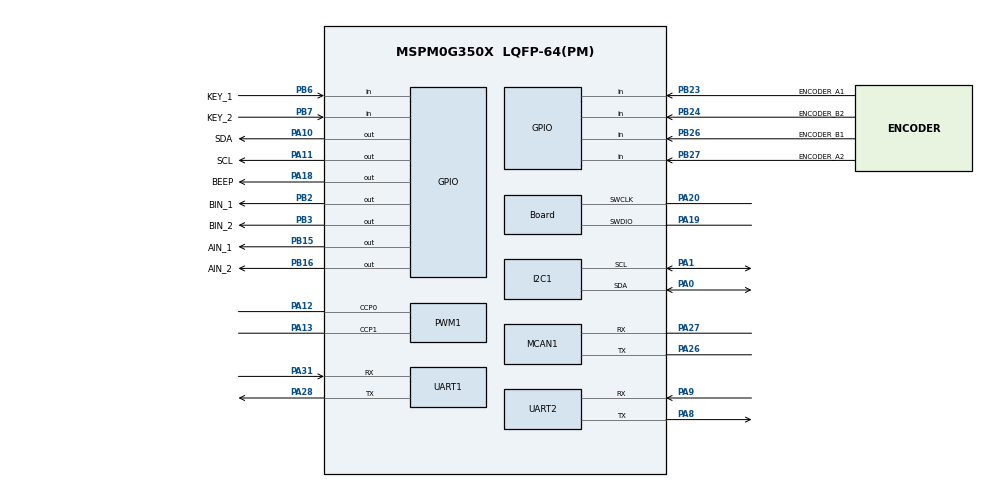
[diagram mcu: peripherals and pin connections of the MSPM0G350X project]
 /**
 * @cliArgs --device "MSPM0G350X" --part "Default" --package "LQFP-64(PM)" --product "mspm0_sdk@2.06.00.05"
 * @versions {"tool":"1.25.0+4268"}
 */

/**
 * Import the modules used in this configuration.
 */
const Board         = scripting.addModule("/ti/driverlib/Board");
const GPIO          = scripting.addModule("/ti/driverlib/GPIO", {}, false);
const GPIO1         = GPIO.addInstance();
const GPIO2         = GPIO.addInstance();
const GPIO3         = GPIO.addInstance();
const GPIO4         = GPIO.addInstance();
const GPIO5         = GPIO.addInstance();
const GPIO6         = GPIO.addInstance();
const I2C           = scripting.addModule("/ti/driverlib/I2C", {}, false);
const I2C1          = I2C.addInstance();
const MCAN          = scripting.addModule("/ti/driverlib/MCAN", {}, false);
const MCAN1         = MCAN.addInstance();
const PWM           = scripting.addModule("/ti/driverlib/PWM", {}, false);
const PWM1          = PWM.addInstance();
const SYSCTL        = scripting.addModule("/ti/driverlib/SYSCTL");
const TIMER         = scripting.addModule("/ti/driverlib/TIMER", {}, false);
const TIMER1        = TIMER.addInstance();
const UART          = scripting.addModule("/ti/driverlib/UART", {}, false);
const UART1         = UART.addInstance();
const UART2         = UART.addInstance();
const ProjectConfig = scripting.addModule("/ti/project_config/ProjectConfig");

/**
 * Write custom configuration values to the imported modules.
 */
const divider6       = system.clockTree["PLL_CLK2X_DIV"];
divider6.divideValue = 4;

const divider9       = system.clockTree["UDIV"];
divider9.divideValue = 2;

const multiplier2         = system.clockTree["PLL_QDIV"];
multiplier2.multiplyValue = 5;

const mux8       = system.clockTree["HSCLKMUX"];
mux8.inputSelect = "HSCLKMUX_SYSPLL2X";

Board.peripheral.$assign          = "DEBUGSS";
Board.peripheral.swclkPin.$assign = "PA20";
Board.peripheral.swdioPin.$assign = "PA19";

GPIO1.$name                          = "GRAY_SENSOR";
GPIO1.associatedPins.create(4);
GPIO1.associatedPins[0].$name        = "GRAY_SENSOR_AD1";
GPIO1.associatedPins[0].assignedPin  = "15";
GPIO1.associatedPins[0].assignedPort = "PORTA";
GPIO1.associatedPins[1].$name        = "GRAY_SENSOR_AD2";
GPIO1.associatedPins[1].assignedPort = "PORTA";
GPIO1.associatedPins[1].assignedPin  = "16";
GPIO1.associatedPins[2].$name        = "GRAY_SENSOR_AD0";
GPIO1.associatedPins[2].assignedPort = "PORTA";
GPIO1.associatedPins[2].assignedPin  = "14";
GPIO1.associatedPins[3].$name        = "GRAY_SENSOR_DATA";
GPIO1.associatedPins[3].direction    = "INPUT";
GPIO1.associatedPins[3].assignedPort = "PORTA";
GPIO1.associatedPins[3].assignedPin  = "17";

GPIO2.$name                              = "KEY";
GPIO2.associatedPins.create(4);
GPIO2.associatedPins[0].direction        = "INPUT";
GPIO2.associatedPins[0].internalResistor = "PULL_UP";
GPIO2.associatedPins[0].inputFilter      = "1_CYCLE";
GPIO2.associatedPins[0].$name            = "KEY_1";
GPIO2.associatedPins[0].assignedPort     = "PORTB";
GPIO2.associatedPins[0].assignedPin      = "6";
GPIO2.associatedPins[0].pin.$assign      = "PB6";
GPIO2.associatedPins[1].$name            = "KEY_2";
GPIO2.associatedPins[1].direction        = "INPUT";
GPIO2.associatedPins[1].internalResistor = "PULL_UP";
GPIO2.associatedPins[1].inputFilter      = "1_CYCLE";
GPIO2.associatedPins[1].assignedPort     = "PORTB";
GPIO2.associatedPins[1].assignedPin      = "7";
GPIO2.associatedPins[1].pin.$assign      = "PB7";
GPIO2.associatedPins[2].$name            = "KEY_3";
GPIO2.associatedPins[2].direction        = "INPUT";
GPIO2.associatedPins[2].internalResistor = "PULL_UP";
GPIO2.associatedPins[2].inputFilter      = "1_CYCLE";
GPIO2.associatedPins[2].assignedPort     = "PORTB";
GPIO2.associatedPins[2].assignedPin      = "8";
GPIO2.associatedPins[3].$name            = "KEY_4";
GPIO2.associatedPins[3].direction        = "INPUT";
GPIO2.associatedPins[3].internalResistor = "PULL_UP";
GPIO2.associatedPins[3].assignedPort     = "PORTB";
GPIO2.associatedPins[3].assignedPin      = "9";

GPIO3.$name                         = "MOTOR";
GPIO3.associatedPins.create(5);
GPIO3.associatedPins[0].$name       = "STBY";
GPIO3.associatedPins[1].$name       = "AIN_1";
GPIO3.associatedPins[1].pin.$assign = "PB15";
GPIO3.associatedPins[2].$name       = "AIN_2";
GPIO3.associatedPins[2].pin.$assign = "PB16";
GPIO3.associatedPins[3].$name       = "BIN_1";
GPIO3.associatedPins[3].pin.$assign = "PB2";
GPIO3.associatedPins[4].$name       = "BIN_2";
GPIO3.associatedPins[4].pin.$assign = "PB3";

GPIO4.$name                          = "BEEP_IO";
GPIO4.associatedPins[0].$name        = "BEEP";
GPIO4.associatedPins[0].assignedPort = "PORTA";
GPIO4.associatedPins[0].assignedPin  = "18";
GPIO4.associatedPins[0].pin.$assign  = "PA18";

GPIO5.$name                         = "ENCODER_READ";
GPIO5.associatedPins.create(4);
GPIO5.associatedPins[0].$name       = "ENCODER_B1";
GPIO5.associatedPins[0].direction   = "INPUT";
GPIO5.associatedPins[0].pin.$assign = "PB26";
GPIO5.associatedPins[1].$name       = "ENCODER_A1";
GPIO5.associatedPins[1].direction   = "INPUT";
GPIO5.associatedPins[1].pin.$assign = "PB23";
GPIO5.associatedPins[2].$name       = "ENCODER_B2";
GPIO5.associatedPins[2].direction   = "INPUT";
GPIO5.associatedPins[2].pin.$assign = "PB24";
GPIO5.associatedPins[3].$name       = "ENCODER_A2";
GPIO5.associatedPins[3].direction   = "INPUT";
GPIO5.associatedPins[3].pin.$assign = "PB27";

/* MPU6050 software-I2C bus: PA10=SDA, PA11=SCL. */
GPIO6.$name                          = "MPU6050_I2C";
GPIO6.associatedPins.create(2);
GPIO6.associatedPins[0].$name        = "SDA";
GPIO6.associatedPins[0].assignedPort = "PORTA";
GPIO6.associatedPins[0].assignedPin  = "10";
GPIO6.associatedPins[0].pin.$assign  = "PA10";
GPIO6.associatedPins[1].$name        = "SCL";
GPIO6.associatedPins[1].assignedPort = "PORTA";
GPIO6.associatedPins[1].assignedPin  = "11";
GPIO6.associatedPins[1].pin.$assign  = "PA11";

/*
 * Expansion-board OLED wiring is unchanged:
 * PA0=SDA, PA1=SCL. Only the internal implementation uses I2C0.
 */
I2C1.$name                             = "OLED_I2C";
I2C1.basicClockSourceDivider           = 4;
I2C1.basicEnableController             = true;
I2C1.advDigitalGlitchFilter            = "CLOCKS_1";
I2C1.advControllerRXFIFOTRIG           = "BYTES_8";
I2C1.advControllerTXFIFOTRIG           = "BYTES_7";
I2C1.enableDMAEvent1                   = false;
I2C1.enableDMAEvent2                   = false;
I2C1.basicControllerStandardBusSpeed   = "Fast";
I2C1.basicControllerBusSpeed           = 500000;
I2C1.peripheral.$assign                = "I2C0";
I2C1.peripheral.sdaPin.$assign         = "PA0";
I2C1.peripheral.sclPin.$assign         = "PA1";
I2C1.sdaPinConfig.hideOutputInversion  = scripting.forceWrite(false);
I2C1.sdaPinConfig.onlyInternalResistor = scripting.forceWrite(false);
I2C1.sdaPinConfig.passedPeripheralType = scripting.forceWrite("Digital");
I2C1.sdaPinConfig.$name                = "ti_driverlib_gpio_GPIOPinGeneric0";
I2C1.sclPinConfig.hideOutputInversion  = scripting.forceWrite(false);
I2C1.sclPinConfig.onlyInternalResistor = scripting.forceWrite(false);
I2C1.sclPinConfig.passedPeripheralType = scripting.forceWrite("Digital");
I2C1.sclPinConfig.$name                = "ti_driverlib_gpio_GPIOPinGeneric1";

PWM1.$name                              = "MOTOR_PWM";
PWM1.timerCount                         = 2500;
PWM1.clockDivider                       = 2;
PWM1.peripheral.$assign                 = "TIMG0";
PWM1.peripheral.ccp0Pin.$assign         = "PA12";
PWM1.peripheral.ccp1Pin.$assign         = "PA13";
PWM1.PWM_CHANNEL_0.$name                = "ti_driverlib_pwm_PWMTimerCC0";
PWM1.PWM_CHANNEL_1.$name                = "ti_driverlib_pwm_PWMTimerCC1";
PWM1.ccp0PinConfig.direction            = scripting.forceWrite("OUTPUT");
PWM1.ccp0PinConfig.hideOutputInversion  = scripting.forceWrite(false);
PWM1.ccp0PinConfig.onlyInternalResistor = scripting.forceWrite(false);
PWM1.ccp0PinConfig.passedPeripheralType = scripting.forceWrite("Digital");
PWM1.ccp0PinConfig.$name                = "ti_driverlib_gpio_GPIOPinGeneric4";
PWM1.ccp1PinConfig.direction            = scripting.forceWrite("OUTPUT");
PWM1.ccp1PinConfig.hideOutputInversion  = scripting.forceWrite(false);
PWM1.ccp1PinConfig.onlyInternalResistor = scripting.forceWrite(false);
PWM1.ccp1PinConfig.passedPeripheralType = scripting.forceWrite("Digital");
PWM1.ccp1PinConfig.$name                = "ti_driverlib_gpio_GPIOPinGeneric5";

/*
 * Classic CAN interface compatible with CAN_STM32_K230:
 * nominal bit rate 500 kbit/s, extended identifiers and 8-byte payloads.
 * External CAN transceiver: PA26=CANTX, PA27=CANRX.
 */
MCAN1.$name                    = "MCAN0";
MCAN1.desiredNomRate           = 500;
MCAN1.fdMode                   = false;
MCAN1.brsEnable                = false;
MCAN1.additionalCoreConfig     = true;
MCAN1.anfe                     = "0";
MCAN1.anfs                     = "0";
MCAN1.flesa                    = 0;
MCAN1.lse                      = 1;
MCAN1.lss                      = 0;
MCAN1.rxFIFO0startAddr         = 8;
MCAN1.rxFIFO0size              = 4;
MCAN1.rxFIFO0ElemSize          = "DL_MCAN_ELEM_SIZE_8BYTES";
MCAN1.rxFIFO1size              = 0;
MCAN1.rxBufStartAddr           = 92;
MCAN1.txStartAddr              = 72;
MCAN1.txBufNum                 = 1;
MCAN1.txBufElemSize            = "DL_MCAN_ELEM_SIZE_8BYTES";
MCAN1.txEventFIFOStartAddr     = 88;
MCAN1.txEventFIFOSize          = 1;
MCAN1.enableInterrupt          = false;
MCAN1.peripheral.$assign       = "CANFD0";
MCAN1.peripheral.txPin.$assign = "PA26";
MCAN1.peripheral.rxPin.$assign = "PA27";

UART1.$name                    = "K230_UART";
UART1.targetBaudRate           = 115200;
UART1.enableFIFO               = true;
UART1.rxFifoThreshold          = "DL_UART_RX_FIFO_LEVEL_ONE_ENTRY";
UART1.enabledInterrupts        = ["RX"];
UART1.peripheral.$assign       = "UART0";
UART1.peripheral.txPin.$assign = "PA28";
UART1.peripheral.rxPin.$assign = "PA31";

/* Eight-channel infrared line sensor: module TX->PA9, module RX->PA8. */
UART2.$name                    = "IR_UART";
UART2.targetBaudRate           = 115200;
UART2.enableFIFO               = true;
UART2.rxFifoThreshold          = "DL_UART_RX_FIFO_LEVEL_ONE_ENTRY";
UART2.enabledInterrupts        = ["RX"];
UART2.peripheral.$assign       = "UART1";
UART2.peripheral.txPin.$assign = "PA8";
UART2.peripheral.rxPin.$assign = "PA9";

SYSCTL.MCLKSource         = "HSCLK";
SYSCTL.CANCLKSource       = "SYSPLLCLK1";
SYSCTL.validateClkStatus  = true;
SYSCTL.SYSPLL_CLK0En      = true;
SYSCTL.SYSPLL_CLK1En      = true;
SYSCTL.peripheral.$assign = "SYSCTL";

TIMER1.$name              = "TIMER_0";
TIMER1.timerClkPrescale   = 256;
TIMER1.timerMode          = "PERIODIC";
TIMER1.timerPeriod        = "5 ms";
TIMER1.interrupts         = ["ZERO"];
TIMER1.peripheral.$assign = "TIMG7";

/**
 * Pinmux solution for unlocked pins/peripherals. This ensures that minor changes to the automatic solver in a future
 * version of the tool will not impact the pinmux you originally saw.  These lines can be completely deleted in order to
 * re-solve from scratch.
 */
GPIO1.associatedPins[0].pin.$suggestSolution = "PA15";
GPIO1.associatedPins[1].pin.$suggestSolution = "PA16";
GPIO1.associatedPins[2].pin.$suggestSolution = "PA14";
GPIO1.associatedPins[3].pin.$suggestSolution = "PA17";
GPIO2.associatedPins[2].pin.$suggestSolution = "PB8";
GPIO2.associatedPins[3].pin.$suggestSolution = "PB9";
GPIO3.associatedPins[0].pin.$suggestSolution = "PB13";
